# COMPUTE_CLUSTER0_GIC500SS_GIC_REDISTRIBUTOR_SGI_PPI_2 register map
Vendor: Texas Instruments
Peripheral module from a debugger description file (folder J721S2).
Registers are 32-bit, access not given, no defined reset value unless marked. A register's access mark holds for its fields unless they carry their own. Offsets are as the file gives them; lines under a group give offsets from that group; [hi:lo] are bit positions; {n}, {i} and the like mark numbered series; 'fields as' and 'values as' point back to an identical list; <NAME> marks a mode.

## COMPUTE_CLUSTER0_GIC500SS_GIC_REDISTRIBUTOR_SGI_PPI_2
0x80 GIC_REDISTRIBUTOR_SGI_PPI_2_Redistributor_SGI_PPI_2__1_GICR_IGROUPR0 — Interrupt Group Registers
0x100 GIC_REDISTRIBUTOR_SGI_PPI_2_Redistributor_SGI_PPI_2__2_GICR_ISENABLER0 — Interrupt Set-Enable Registers
0x180 GIC_REDISTRIBUTOR_SGI_PPI_2_Redistributor_SGI_PPI_2__3_GICR_ICENABLER0 — Interrupt Clear-Enable Registers
0x200 GIC_REDISTRIBUTOR_SGI_PPI_2_Redistributor_SGI_PPI_2__4_GICR_ISPENDR0 — Interrupt Set-Pending Registers
0x280 GIC_REDISTRIBUTOR_SGI_PPI_2_Redistributor_SGI_PPI_2__5_GICR_ICPENDR0 — Interrupt Clear-Pending Registers
0x300 GIC_REDISTRIBUTOR_SGI_PPI_2_Redistributor_SGI_PPI_2__6_GICR_ISACTIVER0 — Interrupt Set-Active Registers
0x380 GIC_REDISTRIBUTOR_SGI_PPI_2_Redistributor_SGI_PPI_2__7_GICR_ICACTIVER0 — Interrupt Clear-Active Registers
{0x400+4i} GIC_REDISTRIBUTOR_SGI_PPI_2_Redistributor_SGI_PPI_2__8_GICR_IPRIORITYR{i} (i=0..7) — Interrupt Priority Registers
0xC00 GIC_REDISTRIBUTOR_SGI_PPI_2_Redistributor_SGI_PPI_2__9_GICR_ICFGR0 — Interrupt Configuration Registers
0xC04 GIC_REDISTRIBUTOR_SGI_PPI_2_Redistributor_SGI_PPI_2__10_GICR_ICFGR1 — Interrupt Configuration Registers
0xD00 GIC_REDISTRIBUTOR_SGI_PPI_2_Redistributor_SGI_PPI_2__11_GICR_IGRPMODR0 — Interrupt Group Modifier Registers
0xE00 GIC_REDISTRIBUTOR_SGI_PPI_2_Redistributor_SGI_PPI_2__12_GICR_NSACR — Non-Secure Access Control Registers
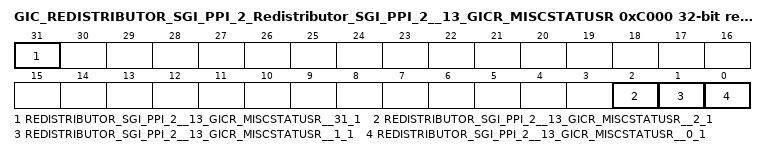
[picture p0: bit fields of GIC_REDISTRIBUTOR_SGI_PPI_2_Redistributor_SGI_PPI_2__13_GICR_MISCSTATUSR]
0xC000 GIC_REDISTRIBUTOR_SGI_PPI_2_Redistributor_SGI_PPI_2__13_GICR_MISCSTATUSR rw reset 0x0 — GIC-500 Miscellaneous Status Register
  [31] REDISTRIBUTOR_SGI_PPI_2__13_GICR_MISCSTATUSR__31_1, [2] REDISTRIBUTOR_SGI_PPI_2__13_GICR_MISCSTATUSR__2_1, [1] REDISTRIBUTOR_SGI_PPI_2__13_GICR_MISCSTATUSR__1_1, [0] REDISTRIBUTOR_SGI_PPI_2__13_GICR_MISCSTATUSR__0_1
0xC080 GIC_REDISTRIBUTOR_SGI_PPI_2_Redistributor_SGI_PPI_2__14_GICR_PPISR rw reset 0x0 — GIC-500 Private Peripheral Interrupt Status Register
  [31:16] REDISTRIBUTOR_SGI_PPI_2__14_GICR_PPISR__16_16
